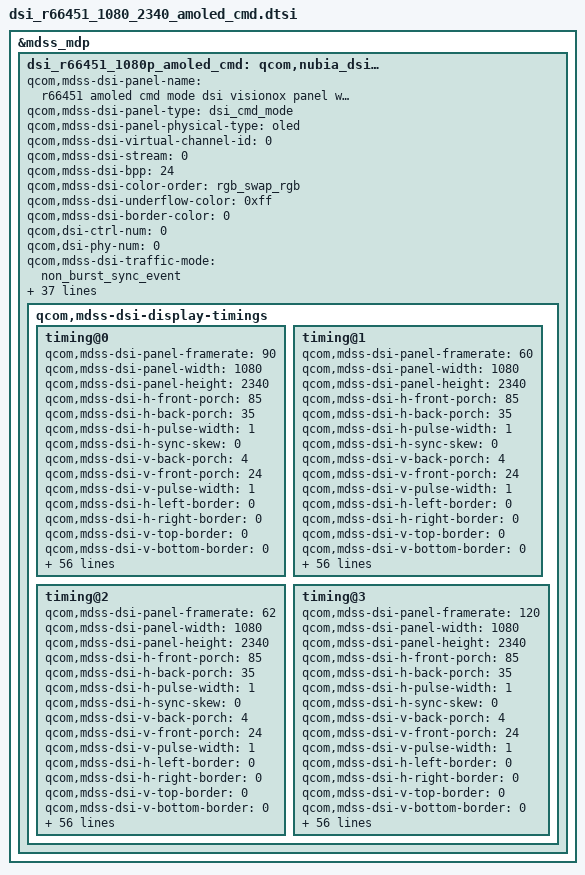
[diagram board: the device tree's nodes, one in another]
&mdss_mdp {
	dsi_r66451_1080p_amoled_cmd: qcom,nubia_dsi_r66451_1080p_amoled_cmd {
		qcom,mdss-dsi-panel-name =
			"r66451 amoled cmd mode dsi visionox panel with DSC";
		qcom,mdss-dsi-panel-type = "dsi_cmd_mode";
		qcom,mdss-dsi-panel-physical-type = "oled";
		qcom,mdss-dsi-virtual-channel-id = <0>;
		qcom,mdss-dsi-stream = <0>;
		qcom,mdss-dsi-bpp = <24>;
		qcom,mdss-dsi-color-order = "rgb_swap_rgb";
		qcom,mdss-dsi-underflow-color = <0xff>;
		qcom,mdss-dsi-border-color = <0>;

		qcom,dsi-ctrl-num = <0>;
		qcom,dsi-phy-num = <0>;

		qcom,mdss-dsi-traffic-mode = "non_burst_sync_event";
		qcom,mdss-dsi-lane-map = "lane_map_0123";
		qcom,mdss-dsi-bllp-eof-power-mode;
		qcom,mdss-dsi-bllp-power-mode;
		qcom,mdss-dsi-lane-0-state;
		qcom,mdss-dsi-lane-1-state;
		qcom,mdss-dsi-lane-2-state;
		qcom,mdss-dsi-lane-3-state;
		qcom,mdss-dsi-dma-trigger = "trigger_sw";
		qcom,mdss-dsi-mdp-trigger = "none";
		qcom,mdss-dsi-reset-sequence = <1 10>, <0 10>, <1 10>;
		qcom,mdss-dsi-te-pin-select = <1>;
		qcom,mdss-dsi-wr-mem-start = <0x2c>;
		qcom,mdss-dsi-wr-mem-continue = <0x3c>;
		qcom,mdss-dsi-te-dcs-command = <1>;
		qcom,mdss-dsi-te-check-enable;
		qcom,mdss-dsi-te-using-te-pin;
		qcom,mdss-dsi-panel-hdr-enabled;
		qcom,mdss-dsi-panel-hdr-color-primaries = <14500 15500 32000
			17000 15500 30000 8000 3000>;
		qcom,mdss-dsi-panel-peak-brightness = <4200000>;
		qcom,mdss-dsi-panel-blackness-level = <3230>;
		qcom,mdss-dsi-qsync-min-refresh-rate = <55>;

		qcom,mdss-pan-physical-width-dimension = <72>;
		qcom,mdss-pan-physical-height-dimension = <156>;
		qcom,dynamic-mode-switch-enabled;
		qcom,dynamic-mode-switch-type = "dynamic-resolution-switch-immediate";

/*********************ESD CHECK***********************/
        qcom,esd-check-enabled; 
        qcom,mdss-dsi-panel-status-check-mode = "reg_read"; 
        qcom,mdss-dsi-panel-status-command = [06 01 00 01 05 00 01 0a
					06 01 00 01 05 00 01 f9
					06 01 00 01 05 00 01 f8]; 
        qcom,mdss-dsi-panel-status-command-state = "dsi_hs_mode";
        qcom,mdss-dsi-panel-status-value = <0x1c 0x00 0x11 0x00 0x00 0x89 0x30 0x80 0x09 0x24 0x04 0x38>;
        qcom,mdss-dsi-panel-status-read-length = <1 1 10>;
/*********************ESD CHECK***********************/

		qcom,mdss-dsi-display-timings {
			timing@0 {
				qcom,mdss-dsi-panel-framerate = <90>;
				qcom,mdss-dsi-panel-width = <1080>;
				qcom,mdss-dsi-panel-height = <2340>;
				qcom,mdss-dsi-h-front-porch = <85>;
				qcom,mdss-dsi-h-back-porch = <35>;
				qcom,mdss-dsi-h-pulse-width = <1>;
				qcom,mdss-dsi-h-sync-skew = <0>;
				qcom,mdss-dsi-v-back-porch = <4>;
				qcom,mdss-dsi-v-front-porch = <24>;
				qcom,mdss-dsi-v-pulse-width = <1>;
				qcom,mdss-dsi-h-left-border = <0>;
				qcom,mdss-dsi-h-right-border = <0>;
				qcom,mdss-dsi-v-top-border = <0>;
				qcom,mdss-dsi-v-bottom-border = <0>;
				qcom,mdss-dsi-panel-jitter = <0x3C 0x0a>;
				qcom,mdss-mdp-transfer-time-us =<8000>;
				qcom,mdss-dsi-on-command = [
					39 01 00 00 00 00 02 B0 00
					39 01 00 00 00 00 2C C4 00 00 00 00 00 00 00 00 0D 00 00 05 00 00 00 36 00 01 00 00 00 00 00 00 00 00 00 00 00 22 00 00 00 00 11 00 00 0C 00 00 00 00 60
					39 01 00 00 00 00 09 D1 05 00 21 02 24 23 24 48
					39 01 00 00 00 00 1A D7 00 B9 34 00 40 00 00 E0 0E 00 40 00 00 00 00 00 00 19 34 00 00 00 00 E0 0E
					39 01 00 00 00 00 34 D8 00 00 00 00 00 00 00 00 00 3C 00 3C 00 3C 00 3C 00 3C 05 00 00 00 00 00 00 00 00 00 0E 00 0E 00 00 00 00 00 00 00 00 00 00 00 00 00 0E 00 36 00 0E 00 30
					39 01 00 00 00 00 2B DF 50 42 58 81 2D 00 00 00 00 00 00 6B 00 00 00 00 00 00 00 00 21 00 FF D4 0E 00 00 00 00 00 20 00 53 18 20 00 00 00 00 00 00 00
					39 01 00 00 00 00 02 F7 01
					39 01 00 00 00 00 02 FA 0B
					39 01 00 00 00 00 02 F1 02
					39 01 00 00 00 00 09 C7 00 04 00 00 00 20 00 00
					39 01 00 00 00 00 02 F1 32
					39 01 00 00 00 00 09 C7 00 04 00 00 00 20 00 00
					39 01 00 00 00 00 02 F1 62
					39 01 00 00 00 00 09 C7 00 04 00 00 00 20 00 00
					39 01 00 00 00 00 02 B0 80
					39 01 00 00 00 00 0A E4 34 B4 00 00 00 3B 08 04 9A
					39 01 00 00 00 00 02 E6 00
					39 01 00 00 00 00 02 B0 04
					39 01 00 00 00 00 03 DF 50 40
					39 01 00 00 00 00 06 F3 50 00 00 00 00
					39 01 00 00 00 00 02 F2 11
					39 01 00 00 00 00 06 F3 01 00 00 00 01
					39 01 00 00 00 00 03 F4 00 02
					39 01 00 00 00 00 02 F2 19
					39 01 00 00 00 00 03 DF 50 42
					//39 01 00 00 00 00 03 51 0F FF
					39 01 00 00 00 00 02 35 00
					39 01 00 00 00 00 05 2A 00 00 04 37
					39 01 00 00 00 00 05 2B 00 00 09 23
					05 01 00 00 8C 00 02 11 00
					05 01 00 00 00 00 02 29 00
				];

				qcom,mdss-dsi-timing-switch-command = [
					39 01 00 00 00 00 02 B0 00
					39 01 00 00 00 00 2C C4 00 00 00 00 00 00 00 00 0D 00 00 05 00 00 00 36 00 01 00 00 00 00 00 00 00 00 00 00 00 22 00 00 00 00 11 00 00 0C 00 00 00 00 60
					39 01 00 00 00 00 09 D1 05 00 21 02 24 23 24 48
					39 01 00 00 00 00 1A D7 00 B9 34 00 40 00 00 E0 0E 00 40 00 00 00 00 00 00 19 34 00 00 00 00 E0 0E
					39 01 00 00 00 00 34 D8 00 00 00 00 00 00 00 00 00 3C 00 3C 00 3C 00 3C 00 3C 05 00 00 00 00 00 00 00 00 00 0E 00 0E 00 00 00 00 00 00 00 00 00 00 00 00 00 0E 00 36 00 0E 00 30
					39 01 00 00 00 00 2B DF 50 42 58 81 2D 00 00 00 00 00 00 6B 00 00 00 00 00 00 00 00 21 00 FF D4 0E 00 00 00 00 00 20 00 53 18 20 00 00 00 00 00 00 00
					39 01 00 00 00 00 02 F7 01
					39 01 00 00 00 00 02 FA 0B
					39 01 00 00 00 00 02 F1 02
					39 01 00 00 00 00 09 C7 00 04 00 00 00 20 00 00
					39 01 00 00 00 00 02 F1 32
					39 01 00 00 00 00 09 C7 00 04 00 00 00 20 00 00
					39 01 00 00 00 00 02 F1 62
					39 01 00 00 00 00 09 C7 00 04 00 00 00 20 00 00
					39 01 00 00 00 00 02 B0 80
					39 01 00 00 00 00 0A E4 34 B4 00 00 00 3B 08 04 9A
					39 01 00 00 00 00 02 E6 00
					39 01 00 00 00 00 02 B0 04
					39 01 00 00 00 00 03 DF 50 40
					39 01 00 00 00 00 06 F3 50 00 00 00 00
					39 01 00 00 00 00 02 F2 11
					39 01 00 00 00 00 06 F3 01 00 00 00 01
					39 01 00 00 00 00 03 F4 00 02
					39 01 00 00 00 00 02 F2 19
					39 01 00 00 00 00 03 DF 50 42
					//39 01 00 00 00 00 03 51 0F FF
					39 01 00 00 00 00 02 35 00
					39 01 00 00 00 00 05 2A 00 00 04 37
					39 01 00 00 00 00 05 2B 00 00 09 23
					05 01 00 00 8C 00 02 11 00
					05 01 00 00 00 00 02 29 00
				];
				qcom,mdss-dsi-off-command = [
					05 01 00 00 64 00 02 28 00  
					05 01 00 00 32 00 02 10 00];
				qcom,mdss-dsi-on-command-state = "dsi_lp_mode";
				qcom,mdss-dsi-off-command-state = "dsi_hs_mode";
/***********************ACL START*************************/
                nubia,mdss-dsi-cabc-command-off = [
                    15 01 00 00 00 00 02 55 00];
                nubia,mdss-dsi-cabc-command-level1 = [
                    15 01 00 00 00 00 02 55 01];
                nubia,mdss-dsi-cabc-command-level2 = [
                    15 01 00 00 00 00 02 55 02];
                nubia,mdss-dsi-cabc-command-level3 = [
                    15 01 00 00 00 00 02 55 03];
                nubia,mdss-dsi-cabc-command-off-state = "dsi_hs_mode";
                nubia,mdss-dsi-cabc-command-level1-state = "dsi_hs_mode";
                nubia,mdss-dsi-cabc-command-level2-state = "dsi_hs_mode";
                nubia,mdss-dsi-cabc-command-level3-state = "dsi_hs_mode";
/**********************ACL END****************************/
/***********************AOD START*************************/
				qcom,mdss-dsi-nolp-command = [ // 90 out aod
					39 01 00 00 00 00 02 53 04
					39 01 00 00 64 00 03 51 00 00 //add this for flicker
					39 01 00 00 00 00 02 38 00
					39 01 00 00 00 00 02 B0 04
					39 01 00 00 00 00 4A C1 94 42 00 16 05 00 00 00 10 00 10 00 AA 8A 02 10 00 10 00 00 3F 3F 03 FF 03 FF 23 FF 03 FF 23 FF 03 FF 00 40 40 00 00 10 06 00 06 00 00 00 10 00 00 00 00 10 00 00 00 00 10 00 00 20 02 10 01 10 00 00 00 00 00 20 04 20 02
					39 01 00 00 00 00 33 D3 45 00 00 01 13 15 00 15 07 0F 77 77 77 37 B2 11 00 A0 3C 95 00 3E 6A 10 60 10 01 03 73 07 FF 04 44 33 33 83 04 00 00 00 00 00 00 00 3C 00 7E 7E 7E 00
					39 01 00 00 00 00 1A D7 00 B9 34 00 40 00 00 E0 0E 00 40 00 00 00 00 00 00 19 34 00 00 00 00 E0 0E
					39 01 00 00 14 00 34 D8 00 00 00 00 00 00 00 00 00 3C 00 3C 00 3C 00 3C 00 3C 05 00 00 00 00 00 00 00 00 00 0E 00 0E 00 00 00 00 00 00 00 00 00 00 00 00 00 0E 00 36 00 0E 00 30
				];
				qcom,mdss-dsi-lp1-command = [ //in aod
					39 01 00 00 14 00 02 53 04 
					39 01 00 00 00 00 02 39 00 
					39 01 00 00 00 00 02 B0 04
					39 01 00 00 00 00 03 E8 00 02
					39 01 00 00 00 00 03 E4 00 34
					39 01 00 00 00 00 02 B0 04
					39 01 00 00 00 00 7D C1 D4 42 00 3F 0F 00 00 00 10 00 10 00 AA 8A 02 10 00 10 00 00 3F 3F 03 FF 03 FF 23 FF 03 FF 23 FF 03 FF F0 40 40 00 00 10 06 00 06 00 00 00 10 00 00 00 00 10 00 00 00 00 10 00 00 20 02 10 01 10 00 00 00 00 00 20 04 20 03 10 00 00 00 00 00 00 00 10 00 00 00 00 00 00 00 00 00 10 00 00 00 00 00 00 00 00 00 00 00 00 00 00 00 00 00 00 00 00 00 00 00 00 00 00 00 00 00 00 00 00
					39 01 00 00 00 00 35 D3 45 00 00 01 13 15 00 15 07 0F 77 77 77 37 B2 11 00 A0 3C 9C 00 3E 6A 10 60 10 01 03 73 01 11 01 11 33 33 83 04 00 00 00 00 00 00 00 3C 00 7E 7E 7E 03 42 01
					39 01 00 00 00 00 1A D7 00 B9 34 00 40 00 02 C0 2C 00 40 00 00 00 00 00 00 19 34 00 00 00 02 C0 2C
					39 01 00 00 14 00 3C D8 00 00 00 00 00 00 00 00 00 5B 00 5B 00 5B 00 5B 00 5B 05 00 00 00 00 00 00 00 00 00 2C 00 2C 00 00 00 00 00 00 00 00 00 00 00 00 00 2C 00 6D 00 2C 00 0C 00 00 00 00 00 00 00 00
				];
				qcom,mdss-dsi-nolp-command-state = "dsi_hs_mode";
				qcom,mdss-dsi-lp1-command-state = "dsi_hs_mode";
/**********************AOD END****************************/
/***********************HBM START*************************/
				nubia,mdss-dsi-hbm-fp-command-off = [
				    39 01 00 00 00 00 02 B0 00
				    15 01 00 00 00 00 02 53 00];
				nubia,mdss-dsi-hbm-fp-command-on = [
				    39 01 00 00 00 00 02 B0 00
				    15 01 00 00 00 00 02 53 E0];
                nubia,mdss-dsi-hbm-command-off = [
                    39 01 00 00 00 00 02 B0 00
                    15 01 00 00 00 00 02 53 00];
                nubia,mdss-dsi-hbm-command-on = [
                    39 01 00 00 00 00 02 B0 00
                    15 01 00 00 00 00 02 53 E0];
			    nubia,mdss-dsi-hbm-fp-command-off-state = "dsi_hs_mode";
			    nubia,mdss-dsi-hbm-fp-command-on-state = "dsi_hs_mode";
			    nubia,mdss-dsi-hbm-command-off-state = "dsi_hs_mode";
                nubia,mdss-dsi-hbm-command-on-state = "dsi_hs_mode";
/**********************HBM END****************************/
				qcom,mdss-dsi-h-sync-pulse = <0>;
				qcom,compression-mode = "dsc";
				qcom,mdss-dsc-slice-height = <20>;
				qcom,mdss-dsc-slice-width = <540>;
				qcom,mdss-dsc-slice-per-pkt = <2>;
				qcom,mdss-dsc-bit-per-component = <8>;
				qcom,mdss-dsc-bit-per-pixel = <8>;
				qcom,mdss-dsc-block-prediction-enable;
			};

			timing@1 {
				qcom,mdss-dsi-panel-framerate = <60>;
				qcom,mdss-dsi-panel-width = <1080>;
				qcom,mdss-dsi-panel-height = <2340>;
				qcom,mdss-dsi-h-front-porch = <85>;
				qcom,mdss-dsi-h-back-porch = <35>;
				qcom,mdss-dsi-h-pulse-width = <1>;
				qcom,mdss-dsi-h-sync-skew = <0>;
				qcom,mdss-dsi-v-back-porch = <4>;
				qcom,mdss-dsi-v-front-porch = <24>;
				qcom,mdss-dsi-v-pulse-width = <1>;
				qcom,mdss-dsi-h-left-border = <0>;
				qcom,mdss-dsi-h-right-border = <0>;
				qcom,mdss-dsi-v-top-border = <0>;
				qcom,mdss-dsi-v-bottom-border = <0>;
				qcom,mdss-dsi-panel-jitter = <0x3C 0x0a>;
				qcom,mdss-mdp-transfer-time-us =<14500>;
				/*default for 60Hz*/
				qcom,mdss-dsi-on-command = [
					39 01 00 00 00 00 02 B0 00
					39 01 00 00 00 00 2C C4 00 00 00 00 00 00 00 00 0D 00 00 05 00 00 00 36 00 01 00 00 00 00 00 00 00 00 00 00 00 22 00 00 00 00 11 00 00 0C 00 00 00 00 60
					39 01 00 00 00 00 09 D1 05 00 21 02 24 23 24 48
					39 01 00 00 00 00 1A D7 00 B9 34 00 40 00 00 E0 0E 00 40 00 00 00 00 00 00 19 34 00 00 00 00 E0 0E
					39 01 00 00 00 00 34 D8 00 00 00 00 00 00 00 00 00 5B 00 5B 00 5B 00 5B 00 5B 05 00 00 00 00 00 00 00 00 00 0E 00 0E 00 00 00 00 00 00 00 00 00 00 00 00 00 0E 00 36 00 0E 00 30
					39 01 00 00 00 00 2B DF 50 42 58 81 2D 00 00 00 00 00 00 6B 00 00 00 00 00 00 00 00 21 00 FF D4 0E 00 00 00 00 00 20 00 53 18 20 00 00 00 00 00 00 00
					39 01 00 00 00 00 02 F7 01
					39 01 00 00 00 00 02 FA 0B
					39 01 00 00 00 00 02 F1 02
					39 01 00 00 00 00 09 C7 00 04 00 00 00 20 00 00
					39 01 00 00 00 00 02 F1 32
					39 01 00 00 00 00 09 C7 00 04 00 00 00 20 00 00
					39 01 00 00 00 00 02 F1 62
					39 01 00 00 00 00 09 C7 00 04 00 00 00 20 00 00
					39 01 00 00 00 00 02 B0 80
					39 01 00 00 00 00 0A E4 34 B4 00 00 00 3B 08 04 9A
					39 01 00 00 00 00 02 E6 00
					39 01 00 00 00 00 02 B0 04
					39 01 00 00 00 00 03 DF 50 40
					39 01 00 00 00 00 06 F3 50 00 00 00 00
					39 01 00 00 00 00 02 F2 11
					39 01 00 00 00 00 06 F3 01 00 00 00 01
					39 01 00 00 00 00 03 F4 00 02
					39 01 00 00 00 00 02 F2 19
					39 01 00 00 00 00 03 DF 50 42
					//39 01 00 00 00 00 03 51 0F FF
					39 01 00 00 00 00 02 35 00
					39 01 00 00 00 00 05 2A 00 00 04 37
					39 01 00 00 00 00 05 2B 00 00 09 23
					05 01 00 00 8C 00 02 11 00
					05 01 00 00 00 00 02 29 00
				];

				qcom,mdss-dsi-timing-switch-command = [
					39 01 00 00 00 00 02 B0 00
					39 01 00 00 00 00 2C C4 00 00 00 00 00 00 00 00 0D 00 00 05 00 00 00 36 00 01 00 00 00 00 00 00 00 00 00 00 00 22 00 00 00 00 11 00 00 0C 00 00 00 00 60
					39 01 00 00 00 00 09 D1 05 00 21 02 24 23 24 48
					39 01 00 00 00 00 1A D7 00 B9 34 00 40 00 00 E0 0E 00 40 00 00 00 00 00 00 19 34 00 00 00 00 E0 0E
					39 01 00 00 00 00 34 D8 00 00 00 00 00 00 00 00 00 5B 00 5B 00 5B 00 5B 00 5B 05 00 00 00 00 00 00 00 00 00 0E 00 0E 00 00 00 00 00 00 00 00 00 00 00 00 00 0E 00 36 00 0E 00 30
					39 01 00 00 00 00 2B DF 50 42 58 81 2D 00 00 00 00 00 00 6B 00 00 00 00 00 00 00 00 21 00 FF D4 0E 00 00 00 00 00 20 00 53 18 20 00 00 00 00 00 00 00
					39 01 00 00 00 00 02 F7 01
					39 01 00 00 00 00 02 FA 0B
					39 01 00 00 00 00 02 F1 02
					39 01 00 00 00 00 09 C7 00 04 00 00 00 20 00 00
					39 01 00 00 00 00 02 F1 32
					39 01 00 00 00 00 09 C7 00 04 00 00 00 20 00 00
					39 01 00 00 00 00 02 F1 62
					39 01 00 00 00 00 09 C7 00 04 00 00 00 20 00 00
					39 01 00 00 00 00 02 B0 80
					39 01 00 00 00 00 0A E4 34 B4 00 00 00 3B 08 04 9A
					39 01 00 00 00 00 02 E6 00
					39 01 00 00 00 00 02 B0 04
					39 01 00 00 00 00 03 DF 50 40
					39 01 00 00 00 00 06 F3 50 00 00 00 00
					39 01 00 00 00 00 02 F2 11
					39 01 00 00 00 00 06 F3 01 00 00 00 01
					39 01 00 00 00 00 03 F4 00 02
					39 01 00 00 00 00 02 F2 19
					39 01 00 00 00 00 03 DF 50 42
					//39 01 00 00 00 00 03 51 0F FF
					39 01 00 00 00 00 02 35 00
					39 01 00 00 00 00 05 2A 00 00 04 37
					39 01 00 00 00 00 05 2B 00 00 09 23
					05 01 00 00 8C 00 02 11 00
					05 01 00 00 00 00 02 29 00
				];

				qcom,mdss-dsi-off-command = [
					05 01 00 00 64 00 02 28 00  
					05 01 00 00 32 00 02 10 00];
				qcom,mdss-dsi-on-command-state = "dsi_lp_mode";
				qcom,mdss-dsi-off-command-state = "dsi_hs_mode";
/***********************ACL START*************************/
                nubia,mdss-dsi-cabc-command-off = [
                    15 01 00 00 00 00 02 55 00];
                nubia,mdss-dsi-cabc-command-level1 = [
                    15 01 00 00 00 00 02 55 01];
                nubia,mdss-dsi-cabc-command-level2 = [
                    15 01 00 00 00 00 02 55 02];
                nubia,mdss-dsi-cabc-command-level3 = [
                    15 01 00 00 00 00 02 55 03];
                nubia,mdss-dsi-cabc-command-off-state = "dsi_hs_mode";
                nubia,mdss-dsi-cabc-command-level1-state = "dsi_hs_mode";
                nubia,mdss-dsi-cabc-command-level2-state = "dsi_hs_mode";
                nubia,mdss-dsi-cabc-command-level3-state = "dsi_hs_mode";
/**********************ACL END****************************/
/***********************AOD START*************************/

				qcom,mdss-dsi-nolp-command = [ //60 out aod
					39 01 00 00 00 00 02 53 04
					39 01 00 00 64 00 03 51 00 00 //add this for flicker
					39 01 00 00 00 00 02 38 00
					39 01 00 00 00 00 02 B0 04
					39 01 00 00 00 00 4A C1 94 42 00 16 05 00 00 00 10 00 10 00 AA 8A 02 10 00 10 00 00 3F 3F 03 FF 03 FF 23 FF 03 FF 23 FF 03 FF 00 40 40 00 00 10 06 00 06 00 00 00 10 00 00 00 00 10 00 00 00 00 10 00 00 20 02 10 01 10 00 00 00 00 00 20 04 20 02
					39 01 00 00 00 00 35 D3 45 00 00 01 13 15 00 15 07 0F 77 77 77 37 B2 11 00 A0 3C 95 00 3E 6A 10 60 10 01 03 73 07 FF 04 44 33 33 83 04 00 00 00 00 00 00 00 3C 00 7E 7E 7E 00 42 01
					39 01 00 00 00 00 1A D7 00 B9 34 00 40 00 00 E0 0E 00 40 00 00 00 00 00 00 19 34 00 00 00 00 E0 0E
					39 01 00 00 14 00 3C D8 00 00 00 00 00 00 00 00 00 5B 00 5B 00 5B 00 5B 00 5B 05 00 00 00 00 00 00 00 00 00 0E 00 0E 00 00 00 00 00 00 00 00 00 00 00 00 00 0E 00 36 00 0E 00 30 00 00 00 00 00 00 00 00
				];

				qcom,mdss-dsi-lp1-command = [ //in aod
					39 01 00 00 14 00 02 53 04 
					39 01 00 00 00 00 02 39 00 
					39 01 00 00 00 00 02 B0 04
					39 01 00 00 00 00 03 E8 00 02
					39 01 00 00 00 00 03 E4 00 34
					39 01 00 00 00 00 02 B0 04
					39 01 00 00 00 00 7D C1 D4 42 00 3F 0F 00 00 00 10 00 10 00 AA 8A 02 10 00 10 00 00 3F 3F 03 FF 03 FF 23 FF 03 FF 23 FF 03 FF F0 40 40 00 00 10 06 00 06 00 00 00 10 00 00 00 00 10 00 00 00 00 10 00 00 20 02 10 01 10 00 00 00 00 00 20 04 20 03 10 00 00 00 00 00 00 00 10 00 00 00 00 00 00 00 00 00 10 00 00 00 00 00 00 00 00 00 00 00 00 00 00 00 00 00 00 00 00 00 00 00 00 00 00 00 00 00 00 00 00
					39 01 00 00 00 00 35 D3 45 00 00 01 13 15 00 15 07 0F 77 77 77 37 B2 11 00 A0 3C 9C 00 3E 6A 10 60 10 01 03 73 01 11 01 11 33 33 83 04 00 00 00 00 00 00 00 3C 00 7E 7E 7E 03 42 01
					39 01 00 00 00 00 1A D7 00 B9 34 00 40 00 02 C0 2C 00 40 00 00 00 00 00 00 19 34 00 00 00 02 C0 2C
					39 01 00 00 14 00 3C D8 00 00 00 00 00 00 00 00 00 5B 00 5B 00 5B 00 5B 00 5B 05 00 00 00 00 00 00 00 00 00 2C 00 2C 00 00 00 00 00 00 00 00 00 00 00 00 00 2C 00 6D 00 2C 00 0C 00 00 00 00 00 00 00 00
				];
				qcom,mdss-dsi-nolp-command-state = "dsi_hs_mode";
				qcom,mdss-dsi-lp1-command-state = "dsi_hs_mode";
/**********************AOD END****************************/
/***********************HBM START*************************/
				nubia,mdss-dsi-hbm-fp-command-off = [
				    39 01 00 00 00 00 02 B0 00
				    15 01 00 00 00 00 02 53 00];
				nubia,mdss-dsi-hbm-fp-command-on = [
				    39 01 00 00 00 00 02 B0 00
				    15 01 00 00 00 00 02 53 E0];
                nubia,mdss-dsi-hbm-command-off = [
                    39 01 00 00 00 00 02 B0 00
                    15 01 00 00 00 00 02 53 00];
                nubia,mdss-dsi-hbm-command-on = [
                    39 01 00 00 00 00 02 B0 00
                    15 01 00 00 00 00 02 53 E0];
			    nubia,mdss-dsi-hbm-fp-command-off-state = "dsi_hs_mode";
			    nubia,mdss-dsi-hbm-fp-command-on-state = "dsi_hs_mode";
			    nubia,mdss-dsi-hbm-command-off-state = "dsi_hs_mode";
                nubia,mdss-dsi-hbm-command-on-state = "dsi_hs_mode";
/**********************HBM END****************************/
				qcom,mdss-dsi-h-sync-pulse = <0>;
				qcom,compression-mode = "dsc";
				qcom,mdss-dsc-slice-height = <20>;
				qcom,mdss-dsc-slice-width = <540>;
				qcom,mdss-dsc-slice-per-pkt = <2>;
				qcom,mdss-dsc-bit-per-component = <8>;
				qcom,mdss-dsc-bit-per-pixel = <8>;
				qcom,mdss-dsc-block-prediction-enable;
			};

			timing@2 {
				qcom,mdss-dsi-panel-framerate = <62>;
				qcom,mdss-dsi-panel-width = <1080>;
				qcom,mdss-dsi-panel-height = <2340>;
				qcom,mdss-dsi-h-front-porch = <85>;
				qcom,mdss-dsi-h-back-porch = <35>;
				qcom,mdss-dsi-h-pulse-width = <1>;
				qcom,mdss-dsi-h-sync-skew = <0>;
				qcom,mdss-dsi-v-back-porch = <4>;
				qcom,mdss-dsi-v-front-porch = <24>;
				qcom,mdss-dsi-v-pulse-width = <1>;
				qcom,mdss-dsi-h-left-border = <0>;
				qcom,mdss-dsi-h-right-border = <0>;
				qcom,mdss-dsi-v-top-border = <0>;
				qcom,mdss-dsi-v-bottom-border = <0>;
				qcom,mdss-dsi-panel-jitter = <0x3C 0x0a>;
				qcom,mdss-mdp-transfer-time-us =<14500>;
				/*default for 62Hz*/
				qcom,mdss-dsi-on-command = [
					39 01 00 00 00 00 02 B0 00
					39 01 00 00 00 00 2C C4 00 00 00 00 00 00 00 00 0D 00 00 05 00 00 00 36 00 01 00 00 00 00 00 00 00 00 00 00 00 22 00 00 00 00 11 00 00 0C 00 00 00 00 60
					39 01 00 00 00 00 09 D1 05 00 21 02 24 23 24 48
					39 01 00 00 00 00 1A D7 00 B9 34 00 40 00 00 E0 0E 00 40 00 00 00 00 00 00 19 34 00 00 00 00 E0 0E
					39 01 00 00 00 00 34 D8 00 00 00 00 00 00 00 00 00 58 00 58 00 58 00 58 00 58 05 00 00 00 00 00 00 00 00 00 0E 00 0E 00 00 00 00 00 00 00 00 00 00 00 00 00 0E 00 36 00 0E 00 30
					39 01 00 00 00 00 2B DF 50 42 58 81 2D 00 00 00 00 00 00 6B 00 00 00 00 00 00 00 00 21 00 FF D4 0E 00 00 00 00 00 20 00 53 18 20 00 00 00 00 00 00 00
					39 01 00 00 00 00 02 F7 01
					39 01 00 00 00 00 02 FA 0B
					39 01 00 00 00 00 02 F1 02
					39 01 00 00 00 00 09 C7 00 04 00 00 00 20 00 00
					39 01 00 00 00 00 02 F1 32
					39 01 00 00 00 00 09 C7 00 04 00 00 00 20 00 00
					39 01 00 00 00 00 02 F1 62
					39 01 00 00 00 00 09 C7 00 04 00 00 00 20 00 00
					39 01 00 00 00 00 02 B0 80
					39 01 00 00 00 00 0A E4 34 B4 00 00 00 3B 08 04 9A
					39 01 00 00 00 00 02 E6 00
					39 01 00 00 00 00 02 B0 04
					39 01 00 00 00 00 03 DF 50 40
					39 01 00 00 00 00 06 F3 50 00 00 00 00
					39 01 00 00 00 00 02 F2 11
					39 01 00 00 00 00 06 F3 01 00 00 00 01
					39 01 00 00 00 00 03 F4 00 02
					39 01 00 00 00 00 02 F2 19
					39 01 00 00 00 00 03 DF 50 42
					//39 01 00 00 00 00 03 51 0F FF
					39 01 00 00 00 00 02 35 00
					39 01 00 00 00 00 05 2A 00 00 04 37
					39 01 00 00 00 00 05 2B 00 00 09 23
					05 01 00 00 8C 00 02 11 00
					05 01 00 00 00 00 02 29 00
				];

				qcom,mdss-dsi-timing-switch-command = [
					39 01 00 00 00 00 02 B0 00
					39 01 00 00 00 00 2C C4 00 00 00 00 00 00 00 00 0D 00 00 05 00 00 00 36 00 01 00 00 00 00 00 00 00 00 00 00 00 22 00 00 00 00 11 00 00 0C 00 00 00 00 60
					39 01 00 00 00 00 09 D1 05 00 21 02 24 23 24 48
					39 01 00 00 00 00 1A D7 00 B9 34 00 40 00 00 E0 0E 00 40 00 00 00 00 00 00 19 34 00 00 00 00 E0 0E
					39 01 00 00 00 00 34 D8 00 00 00 00 00 00 00 00 00 5B 00 58 00 58 00 58 00 58 05 00 00 00 00 00 00 00 00 00 0E 00 0E 00 00 00 00 00 00 00 00 00 00 00 00 00 0E 00 36 00 0E 00 30
					39 01 00 00 00 00 2B DF 50 42 58 81 2D 00 00 00 00 00 00 6B 00 00 00 00 00 00 00 00 21 00 FF D4 0E 00 00 00 00 00 20 00 53 18 20 00 00 00 00 00 00 00
					39 01 00 00 00 00 02 F7 01
					39 01 00 00 00 00 02 FA 0B
					39 01 00 00 00 00 02 F1 02
					39 01 00 00 00 00 09 C7 00 04 00 00 00 20 00 00
					39 01 00 00 00 00 02 F1 32
					39 01 00 00 00 00 09 C7 00 04 00 00 00 20 00 00
					39 01 00 00 00 00 02 F1 62
					39 01 00 00 00 00 09 C7 00 04 00 00 00 20 00 00
					39 01 00 00 00 00 02 B0 80
					39 01 00 00 00 00 0A E4 34 B4 00 00 00 3B 08 04 9A
					39 01 00 00 00 00 02 E6 00
					39 01 00 00 00 00 02 B0 04
					39 01 00 00 00 00 03 DF 50 40
					39 01 00 00 00 00 06 F3 50 00 00 00 00
					39 01 00 00 00 00 02 F2 11
					39 01 00 00 00 00 06 F3 01 00 00 00 01
					39 01 00 00 00 00 03 F4 00 02
					39 01 00 00 00 00 02 F2 19
					39 01 00 00 00 00 03 DF 50 42
					//39 01 00 00 00 00 03 51 0F FF
					39 01 00 00 00 00 02 35 00
					39 01 00 00 00 00 05 2A 00 00 04 37
					39 01 00 00 00 00 05 2B 00 00 09 23
					05 01 00 00 8C 00 02 11 00
					05 01 00 00 00 00 02 29 00
				];

				qcom,mdss-dsi-off-command = [
					05 01 00 00 64 00 02 28 00  
					05 01 00 00 32 00 02 10 00];
				qcom,mdss-dsi-on-command-state = "dsi_lp_mode";
				qcom,mdss-dsi-off-command-state = "dsi_hs_mode";
/***********************ACL START*************************/
                nubia,mdss-dsi-cabc-command-off = [
                    15 01 00 00 00 00 02 55 00];
                nubia,mdss-dsi-cabc-command-level1 = [
                    15 01 00 00 00 00 02 55 01];
                nubia,mdss-dsi-cabc-command-level2 = [
                    15 01 00 00 00 00 02 55 02];
                nubia,mdss-dsi-cabc-command-level3 = [
                    15 01 00 00 00 00 02 55 03];
                nubia,mdss-dsi-cabc-command-off-state = "dsi_hs_mode";
                nubia,mdss-dsi-cabc-command-level1-state = "dsi_hs_mode";
                nubia,mdss-dsi-cabc-command-level2-state = "dsi_hs_mode";
                nubia,mdss-dsi-cabc-command-level3-state = "dsi_hs_mode";
/**********************ACL END****************************/
/***********************AOD START*************************/

				qcom,mdss-dsi-nolp-command = [ //60 out aod
					39 01 00 00 00 00 02 53 04
					39 01 00 00 64 00 03 51 00 00 //add this for flicker
					39 01 00 00 00 00 02 38 00
					39 01 00 00 00 00 02 B0 04
					39 01 00 00 00 00 4A C1 94 42 00 16 05 00 00 00 10 00 10 00 AA 8A 02 10 00 10 00 00 3F 3F 03 FF 03 FF 23 FF 03 FF 23 FF 03 FF 00 40 40 00 00 10 06 00 06 00 00 00 10 00 00 00 00 10 00 00 00 00 10 00 00 20 02 10 01 10 00 00 00 00 00 20 04 20 02
					39 01 00 00 00 00 35 D3 45 00 00 01 13 15 00 15 07 0F 77 77 77 37 B2 11 00 A0 3C 95 00 3E 6A 10 60 10 01 03 73 07 FF 04 44 33 33 83 04 00 00 00 00 00 00 00 3C 00 7E 7E 7E 00 42 01
					39 01 00 00 00 00 1A D7 00 B9 34 00 40 00 00 E0 0E 00 40 00 00 00 00 00 00 19 34 00 00 00 00 E0 0E
					39 01 00 00 14 00 3C D8 00 00 00 00 00 00 00 00 00 58 00 58 00 58 00 58 00 58 05 00 00 00 00 00 00 00 00 00 0E 00 0E 00 00 00 00 00 00 00 00 00 00 00 00 00 0E 00 36 00 0E 00 30 00 00 00 00 00 00 00 00
				];

				qcom,mdss-dsi-lp1-command = [ //in aod
					39 01 00 00 14 00 02 53 04 
					39 01 00 00 00 00 02 39 00 
					39 01 00 00 00 00 02 B0 04
					39 01 00 00 00 00 03 E8 00 02
					39 01 00 00 00 00 03 E4 00 34
					39 01 00 00 00 00 02 B0 04
					39 01 00 00 00 00 7D C1 D4 42 00 3F 0F 00 00 00 10 00 10 00 AA 8A 02 10 00 10 00 00 3F 3F 03 FF 03 FF 23 FF 03 FF 23 FF 03 FF F0 40 40 00 00 10 06 00 06 00 00 00 10 00 00 00 00 10 00 00 00 00 10 00 00 20 02 10 01 10 00 00 00 00 00 20 04 20 03 10 00 00 00 00 00 00 00 10 00 00 00 00 00 00 00 00 00 10 00 00 00 00 00 00 00 00 00 00 00 00 00 00 00 00 00 00 00 00 00 00 00 00 00 00 00 00 00 00 00 00
					39 01 00 00 00 00 35 D3 45 00 00 01 13 15 00 15 07 0F 77 77 77 37 B2 11 00 A0 3C 9C 00 3E 6A 10 60 10 01 03 73 01 11 01 11 33 33 83 04 00 00 00 00 00 00 00 3C 00 7E 7E 7E 03 42 01
					39 01 00 00 00 00 1A D7 00 B9 34 00 40 00 02 C0 2C 00 40 00 00 00 00 00 00 19 34 00 00 00 02 C0 2C
					39 01 00 00 14 00 3C D8 00 00 00 00 00 00 00 00 00 5B 00 5B 00 5B 00 5B 00 5B 05 00 00 00 00 00 00 00 00 00 2C 00 2C 00 00 00 00 00 00 00 00 00 00 00 00 00 2C 00 6D 00 2C 00 0C 00 00 00 00 00 00 00 00
				];
				qcom,mdss-dsi-nolp-command-state = "dsi_hs_mode";
				qcom,mdss-dsi-lp1-command-state = "dsi_hs_mode";
/**********************AOD END****************************/
/***********************HBM START*************************/
				nubia,mdss-dsi-hbm-fp-command-off = [
				    39 01 00 00 00 00 02 B0 00
				    15 01 00 00 00 00 02 53 00];
				nubia,mdss-dsi-hbm-fp-command-on = [
				    39 01 00 00 00 00 02 B0 00
				    15 01 00 00 00 00 02 53 E0];
                nubia,mdss-dsi-hbm-command-off = [
                    39 01 00 00 00 00 02 B0 00
                    15 01 00 00 00 00 02 53 00];
                nubia,mdss-dsi-hbm-command-on = [
                    39 01 00 00 00 00 02 B0 00
                    15 01 00 00 00 00 02 53 E0];
			    nubia,mdss-dsi-hbm-fp-command-off-state = "dsi_hs_mode";
			    nubia,mdss-dsi-hbm-fp-command-on-state = "dsi_hs_mode";
			    nubia,mdss-dsi-hbm-command-off-state = "dsi_hs_mode";
                nubia,mdss-dsi-hbm-command-on-state = "dsi_hs_mode";
/**********************HBM END****************************/
				qcom,mdss-dsi-h-sync-pulse = <0>;
				qcom,compression-mode = "dsc";
				qcom,mdss-dsc-slice-height = <20>;
				qcom,mdss-dsc-slice-width = <540>;
				qcom,mdss-dsc-slice-per-pkt = <2>;
				qcom,mdss-dsc-bit-per-component = <8>;
				qcom,mdss-dsc-bit-per-pixel = <8>;
				qcom,mdss-dsc-block-prediction-enable;
			};

			timing@3 {
				qcom,mdss-dsi-panel-framerate = <120>;
				qcom,mdss-dsi-panel-width = <1080>;
				qcom,mdss-dsi-panel-height = <2340>;
				qcom,mdss-dsi-h-front-porch = <85>;
				qcom,mdss-dsi-h-back-porch = <35>;
				qcom,mdss-dsi-h-pulse-width = <1>;
				qcom,mdss-dsi-h-sync-skew = <0>;
				qcom,mdss-dsi-v-back-porch = <4>;
				qcom,mdss-dsi-v-front-porch = <24>;
				qcom,mdss-dsi-v-pulse-width = <1>;
				qcom,mdss-dsi-h-left-border = <0>;
				qcom,mdss-dsi-h-right-border = <0>;
				qcom,mdss-dsi-v-top-border = <0>;
				qcom,mdss-dsi-v-bottom-border = <0>;
				qcom,mdss-dsi-panel-jitter = <0x3C 0x0a>;
				qcom,mdss-mdp-transfer-time-us =<6000>;
				/*default for 120Hz*/
				qcom,mdss-dsi-on-command = [
					39 01 00 00 00 00 02 B0 04
					39 01 00 00 00 00 03 E8 00 02
					39 01 00 00 00 00 03 E4 00 08
					39 01 00 00 00 00 02 B0 00
					39 01 00 00 00 00 2C C4 00 00 00 00 00 00 00 00 0D 00 00 02 00 00 00 32 00 01 00 00 00 00 00 00 00 00 00 00 00 22 00 00 00 00 11 00 00 0C 00 00 00 00 60
					39 01 00 00 00 00 09 D1 05 00 21 02 24 23 24 48
					39 01 00 00 00 00 1A D7 00 B9 34 00 40 04 00 F0 0F 00 40 00 00 00 00 00 00 19 34 00 40 04 00 F0 0F
					39 01 00 00 00 00 34 D8 00 00 00 00 00 00 00 00 00 3A 00 3A 00 3A 00 3A 00 3A 05 00 00 00 00 00 00 00 00 00 0F 00 0F 00 00 00 00 00 00 00 00 00 00 00 00 00 0F 00 2F 00 0F 00 20
					39 01 00 00 00 00 2B DF 50 42 58 81 2D 00 00 00 00 00 00 6B 00 00 00 00 00 00 00 00 01 0F FF D4 0E 00 00 00 00 00 00 0F 53 18 00 0F 00 00 00 00 00 00
					39 01 00 00 00 00 02 F7 01
					39 01 00 00 00 00 02 FA 0B
					39 01 00 00 00 00 02 F1 02
					39 01 00 00 00 00 09 C7 00 04 00 00 00 20 00 00
					39 01 00 00 00 00 02 F1 32
					39 01 00 00 00 00 09 C7 00 04 00 00 00 20 00 00
					39 01 00 00 00 00 02 F1 62
					39 01 00 00 00 00 09 C7 00 04 00 00 00 20 00 00
					39 01 00 00 00 00 02 B0 80
					39 01 00 00 00 00 0A E4 34 B4 00 00 00 30 04 0C E2
					39 01 00 00 00 00 02 E6 00
					39 01 00 00 00 00 02 B0 04
					39 01 00 00 00 00 03 DF 50 40
					39 01 00 00 00 00 06 F3 50 00 00 00 00
					39 01 00 00 00 00 02 F2 11
					39 01 00 00 00 00 06 F3 01 00 00 00 01
					39 01 00 00 00 00 03 F4 00 02
					39 01 00 00 00 00 02 F2 19
					39 01 00 00 00 00 03 DF 50 42
					//39 01 00 00 00 00 03 51 0F FF
					39 01 00 00 00 00 02 35 00
					39 01 00 00 00 00 05 2A 00 00 04 37
					39 01 00 00 00 00 05 2B 00 00 09 23
					05 01 00 00 8C 00 02 11 00
					05 01 00 00 00 00 02 29 00
				];
				qcom,mdss-dsi-timing-switch-command = [
					39 01 00 00 00 00 02 B0 04
					39 01 00 00 00 00 03 E8 00 02
					39 01 00 00 00 00 03 E4 00 08
					39 01 00 00 00 00 02 B0 00
					39 01 00 00 00 00 2C C4 00 00 00 00 00 00 00 00 0D 00 00 02 00 00 00 32 00 01 00 00 00 00 00 00 00 00 00 00 00 22 00 00 00 00 11 00 00 0C 00 00 00 00 60
					39 01 00 00 00 00 09 D1 05 00 21 02 24 23 24 48
					39 01 00 00 00 00 1A D7 00 B9 34 00 40 04 00 F0 0F 00 40 00 00 00 00 00 00 19 34 00 40 04 00 F0 0F
					39 01 00 00 00 00 34 D8 00 00 00 00 00 00 00 00 00 3A 00 3A 00 3A 00 3A 00 3A 05 00 00 00 00 00 00 00 00 00 0F 00 0F 00 00 00 00 00 00 00 00 00 00 00 00 00 0F 00 2F 00 0F 00 20
					39 01 00 00 00 00 2B DF 50 42 58 81 2D 00 00 00 00 00 00 6B 00 00 00 00 00 00 00 00 01 0F FF D4 0E 00 00 00 00 00 00 0F 53 18 00 0F 00 00 00 00 00 00
					39 01 00 00 00 00 02 F7 01
					39 01 00 00 00 00 02 FA 0B
					39 01 00 00 00 00 02 F1 02
					39 01 00 00 00 00 09 C7 00 04 00 00 00 20 00 00
					39 01 00 00 00 00 02 F1 32
					39 01 00 00 00 00 09 C7 00 04 00 00 00 20 00 00
					39 01 00 00 00 00 02 F1 62
					39 01 00 00 00 00 09 C7 00 04 00 00 00 20 00 00
					39 01 00 00 00 00 02 B0 80
					39 01 00 00 00 00 0A E4 34 B4 00 00 00 30 04 0C E2
					39 01 00 00 00 00 02 E6 00
					39 01 00 00 00 00 02 B0 04
					39 01 00 00 00 00 03 DF 50 40
					39 01 00 00 00 00 06 F3 50 00 00 00 00
					39 01 00 00 00 00 02 F2 11
					39 01 00 00 00 00 06 F3 01 00 00 00 01
					39 01 00 00 00 00 03 F4 00 02
					39 01 00 00 00 00 02 F2 19
					39 01 00 00 00 00 03 DF 50 42
					//39 01 00 00 00 00 03 51 0F FF
					39 01 00 00 00 00 02 35 00
					39 01 00 00 00 00 05 2A 00 00 04 37
					39 01 00 00 00 00 05 2B 00 00 09 23
					05 01 00 00 8C 00 02 11 00
					05 01 00 00 00 00 02 29 00
				];

				qcom,mdss-dsi-off-command = [
					05 01 00 00 64 00 02 28 00  
					05 01 00 00 32 00 02 10 00];
				qcom,mdss-dsi-on-command-state = "dsi_lp_mode";
				qcom,mdss-dsi-off-command-state = "dsi_hs_mode";
/***********************ACL START*************************/
                nubia,mdss-dsi-cabc-command-off = [
                    15 01 00 00 00 00 02 55 00];
                nubia,mdss-dsi-cabc-command-level1 = [
                    15 01 00 00 00 00 02 55 01];
                nubia,mdss-dsi-cabc-command-level2 = [
                    15 01 00 00 00 00 02 55 02];
                nubia,mdss-dsi-cabc-command-level3 = [
                    15 01 00 00 00 00 02 55 03];
                nubia,mdss-dsi-cabc-command-off-state = "dsi_hs_mode";
                nubia,mdss-dsi-cabc-command-level1-state = "dsi_hs_mode";
                nubia,mdss-dsi-cabc-command-level2-state = "dsi_hs_mode";
                nubia,mdss-dsi-cabc-command-level3-state = "dsi_hs_mode";
/**********************ACL END****************************/
/***********************AOD START*************************/
				qcom,mdss-dsi-nolp-command = [ //120 out aod
					39 01 00 00 00 00 02 53 04
					39 01 00 00 00 00 02 38 00
					39 01 00 00 00 00 02 B0 00
					39 01 00 00 00 00 4A C1 94 42 00 16 05 00 00 00 10 00 10 00 AA 8A 02 10 00 10 00 00 3F 3F 03 FF 03 FF 23 FF 03 FF 23 FF 03 FF 00 40 40 00 00 10 06 00 06 00 00 00 10 00 00 00 00 10 00 00 00 00 10 00 00 20 02 10 01 10 00 00 00 00 00 20 04 20 02
					39 01 00 00 00 00 35 D3 45 00 00 01 13 15 00 15 07 0F 77 77 77 37 B2 11 00 A0 3C 95 00 3E 6A 10 60 10 01 03 73 07 FF 04 44 33 33 83 04 00 00 00 00 00 00 00 3C 00 7E 7E 7E 00 42 01
					39 01 00 00 00 00 1A D7 00 B9 34 00 40 04 00 F0 0F 00 40 00 00 00 00 00 00 19 34 00 40 04 00 F0 0F
					39 01 00 00 14 00 3C D8 00 00 00 00 00 00 00 00 00 3A 00 3A 00 3A 00 3A 00 3A 05 00 00 00 00 00 00 00 00 00 0F 00 0F 00 00 00 00 00 00 00 00 00 00 00 00 00 0F 00 2F 00 0F 00 20 00 00 00 00 00 00 00 00
				];

				qcom,mdss-dsi-lp1-command = [ //in aod
					39 01 00 00 14 00 02 53 04 
					39 01 00 00 00 00 02 39 00 
					39 01 00 00 00 00 02 B0 04
					39 01 00 00 00 00 03 E8 00 02
					39 01 00 00 00 00 03 E4 00 34
					39 01 00 00 00 00 02 B0 04
					39 01 00 00 00 00 7D C1 D4 42 00 3F 0F 00 00 00 10 00 10 00 AA 8A 02 10 00 10 00 00 3F 3F 03 FF 03 FF 23 FF 03 FF 23 FF 03 FF F0 40 40 00 00 10 06 00 06 00 00 00 10 00 00 00 00 10 00 00 00 00 10 00 00 20 02 10 01 10 00 00 00 00 00 20 04 20 03 10 00 00 00 00 00 00 00 10 00 00 00 00 00 00 00 00 00 10 00 00 00 00 00 00 00 00 00 00 00 00 00 00 00 00 00 00 00 00 00 00 00 00 00 00 00 00 00 00 00 00
					39 01 00 00 00 00 35 D3 45 00 00 01 13 15 00 15 07 0F 77 77 77 37 B2 11 00 A0 3C 9C 00 3E 6A 10 60 10 01 03 73 01 11 01 11 33 33 83 04 00 00 00 00 00 00 00 3C 00 7E 7E 7E 03 42 01
					39 01 00 00 00 00 1A D7 00 B9 34 00 40 00 02 C0 2C 00 40 00 00 00 00 00 00 19 34 00 00 00 02 C0 2C
					39 01 00 00 14 00 3C D8 00 00 00 00 00 00 00 00 00 5B 00 5B 00 5B 00 5B 00 5B 05 00 00 00 00 00 00 00 00 00 2C 00 2C 00 00 00 00 00 00 00 00 00 00 00 00 00 2C 00 6D 00 2C 00 0C 00 00 00 00 00 00 00 00
				];
				qcom,mdss-dsi-nolp-command-state = "dsi_hs_mode";
				qcom,mdss-dsi-lp1-command-state = "dsi_hs_mode";
/**********************AOD END****************************/
/***********************HBM START*************************/
				nubia,mdss-dsi-hbm-fp-command-off = [
				    39 01 00 00 00 00 02 B0 00
				    15 01 00 00 00 00 02 53 00];
				nubia,mdss-dsi-hbm-fp-command-on = [
				    39 01 00 00 00 00 02 B0 00
				    15 01 00 00 00 00 02 53 E0];
                nubia,mdss-dsi-hbm-command-off = [
                    39 01 00 00 00 00 02 B0 00
                    15 01 00 00 00 00 02 53 00];
                nubia,mdss-dsi-hbm-command-on = [
                    39 01 00 00 00 00 02 B0 00
                    15 01 00 00 00 00 02 53 E0];
			    nubia,mdss-dsi-hbm-fp-command-off-state = "dsi_hs_mode";
			    nubia,mdss-dsi-hbm-fp-command-on-state = "dsi_hs_mode";
			    nubia,mdss-dsi-hbm-command-off-state = "dsi_hs_mode";
                nubia,mdss-dsi-hbm-command-on-state = "dsi_hs_mode";
/**********************HBM END****************************/
				qcom,mdss-dsi-h-sync-pulse = <0>;
				qcom,compression-mode = "dsc";
				qcom,mdss-dsc-slice-height = <20>;
				qcom,mdss-dsc-slice-width = <540>;
				qcom,mdss-dsc-slice-per-pkt = <2>;
				qcom,mdss-dsc-bit-per-component = <8>;
				qcom,mdss-dsc-bit-per-pixel = <8>;
				qcom,mdss-dsc-block-prediction-enable;
			};
		};
	};
};
